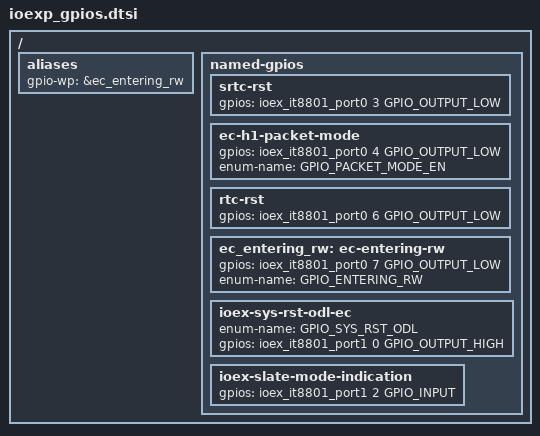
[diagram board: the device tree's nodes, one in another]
/* Copyright 2024 The Chromium OS Authors. All rights reserved
 * Use of this source code is governed by a BSD-style license that can be
 * found in the LICENSE file.
 */

/ {
	aliases {
		gpio-wp = &ec_entering_rw;
	};

	named-gpios {
		/* KBD IOEX configuration, IOEX present on H1 AIC */
		srtc-rst {
			gpios = <&ioex_it8801_port0 3 GPIO_OUTPUT_LOW>;
		};
		ec-h1-packet-mode {
			gpios = <&ioex_it8801_port0 4 GPIO_OUTPUT_LOW>;
			enum-name = "GPIO_PACKET_MODE_EN";
		};
		rtc-rst {
			gpios = <&ioex_it8801_port0 6 GPIO_OUTPUT_LOW>;
		};
		ec_entering_rw: ec-entering-rw {
			gpios = <&ioex_it8801_port0 7 GPIO_OUTPUT_LOW>;
			enum-name = "GPIO_ENTERING_RW";
		};
		ioex-sys-rst-odl-ec {
			enum-name = "GPIO_SYS_RST_ODL";
			gpios = <&ioex_it8801_port1 0 GPIO_OUTPUT_HIGH>;
		};
		ioex-slate-mode-indication {
			gpios = <&ioex_it8801_port1 2 GPIO_INPUT>;
		};
	};
};
